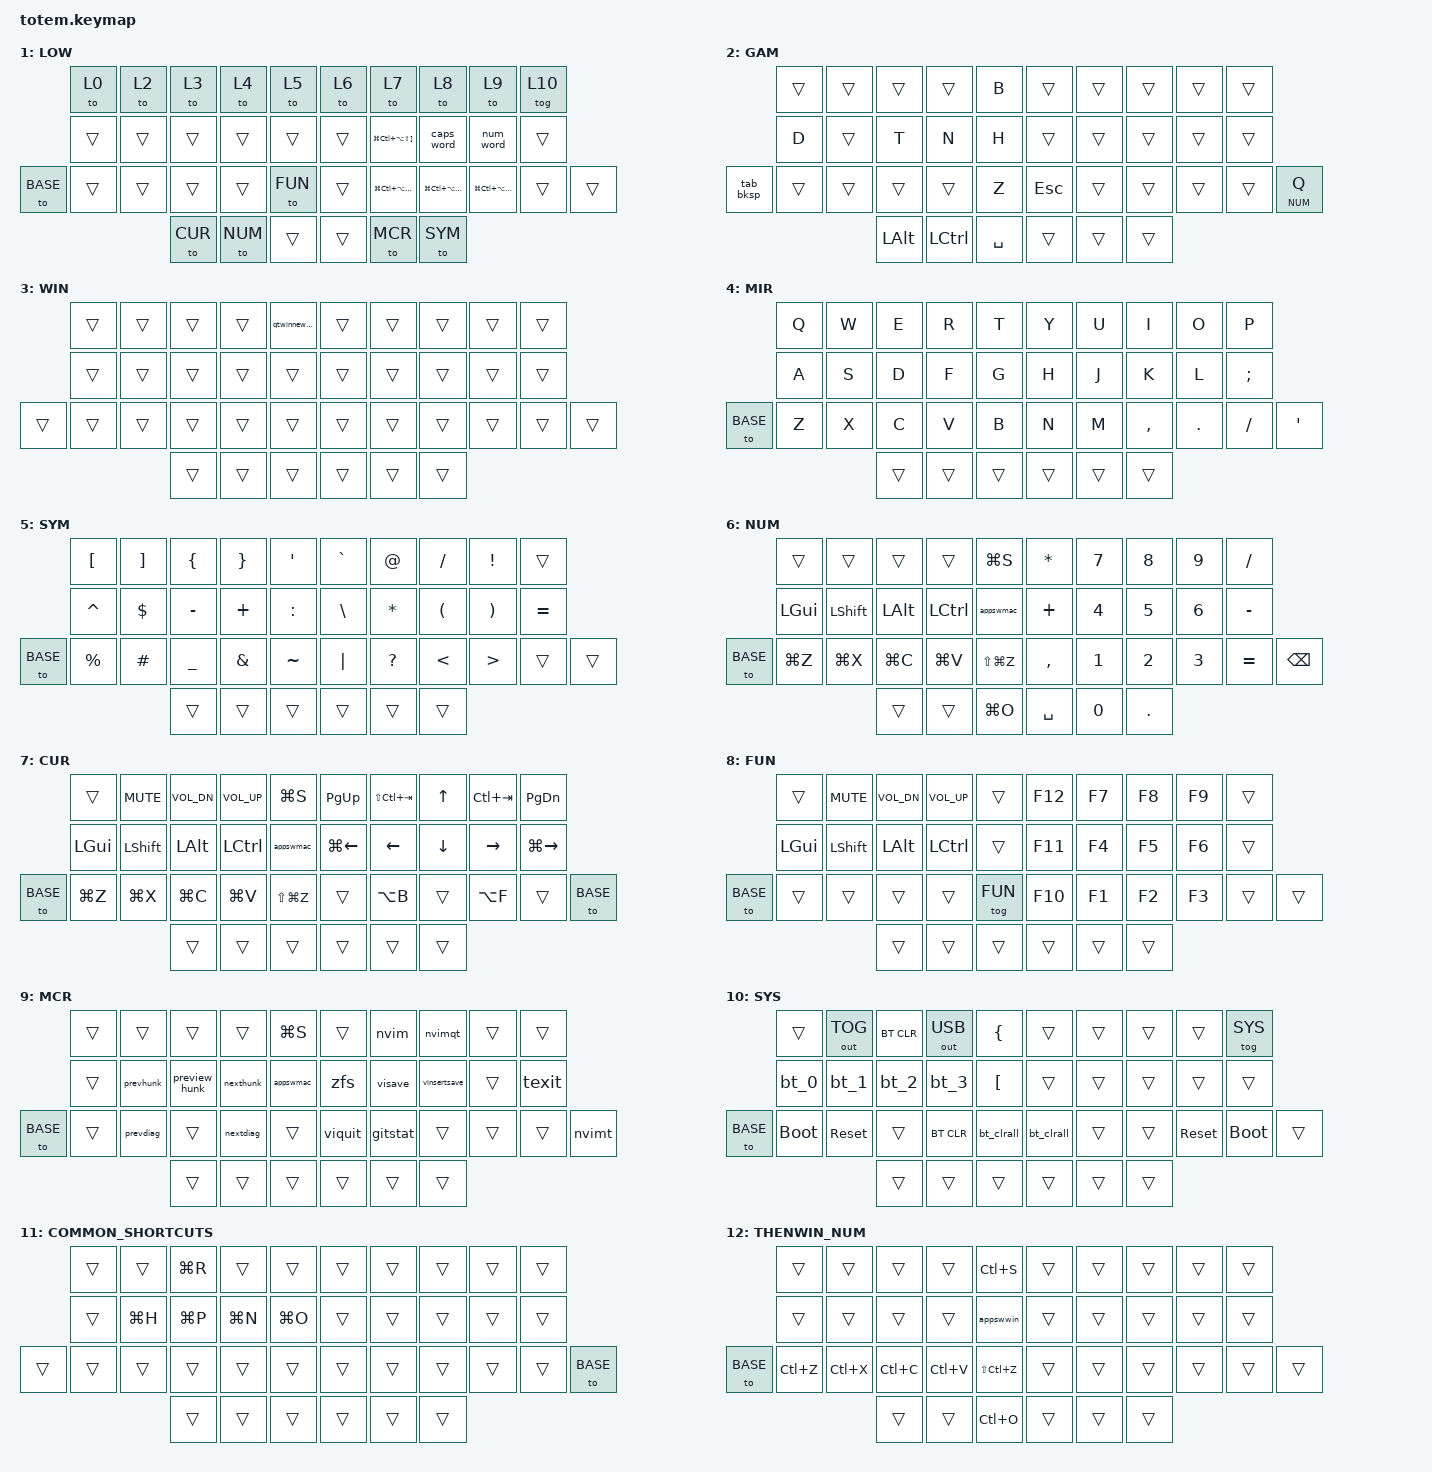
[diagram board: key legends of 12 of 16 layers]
//
//                                                        ▀▀▀▀▀     ▀▀▀▀▀          ▀▀█▀▀
//                                                        ▄▀▀▀▄  ▄  ▄▀▀▀▄  ▄  ▄▀▀▀▄  █  ▄▀▀▀▄
//                                                        █   █  █  █   █  █  █   █  █  █   █
//                                                         ▀▀▀   █   ▀▀▀   █   ▀▀▀   ▀   ▀▀▀
//                                                               █      ▄▄▄█▄▄▄    █   █
//                                                               ▀      █  █  █     █▄█
//                                                             ▀▀▀▀▀    █  █  █      ▀
//                                                                      ▀  ▀  ▀
//
// ▄▄▄▄▄▄▄▄▄▄▄▄▄▄▄▄▄▄▄▄▄▄▄▄▄▄▄▄▄▄▄▄▄▄▄▄▄▄▄▄▄▄▄▄▄▄▄▄▄▄▄▄▄▄▄▄▄▄▄▄▄▄▄▄▄▄▄▄▄▄▄▄▄▄▄▄▄▄▄▄▄▄▄▄▄▄▄▄▄▄▄▄▄▄▄▄▄▄▄▄▄▄▄▄▄▄▄▄▄▄▄▄▄▄▄▄▄▄▄▄▄▄▄▄▄▄▄▄▄▄▄▄▄▄▄▄▄▄▄▄▄▄▄▄▄▄▄▄▄


#include <behaviors.dtsi>
#include <dt-bindings/zmk/bt.h>
#include <dt-bindings/zmk/ext_power.h>
#include <dt-bindings/zmk/keys.h>
#include <dt-bindings/zmk/outputs.h>

#define BASE 0
#define LOW 1
#define GAM 2
#define WIN 3
#define MIR 4
#define SYM 5
#define NUM 6
#define CUR 7
#define FUN 8
#define MCR 9
#define SYS 10
#define COMMON_SHORTCUTS 11
#define THENWIN_NUM 12
#define THENWIN_CUR 13
#define THENWIN_MCR 14
#define THENWIN_SHORTCUTS 15
#define QWERTY 16


&mt {
  quick-tap-ms = <100>;
  global-quick-tap;
  flavor = "tap-preferred";
  tapping-term-ms = <170>;
};

#define HYPER LG(LC(LA(LSHFT)))
#define MEH   LC(LA(LSHFT))
#define HYPF7 &kp LG(LC(LA(LS(F7))))
#define HYPF8 &kp LG(LC(LA(LS(F8))))
#define HYPF9 &kp LG(LC(LA(LS(F9))))
#define ALFRED &kp LG(LC(LA(LS(RBKT))))
#define TMHP &tmb_hold_preferred // layer-tap for thumb keys with hold-preferred!
#define TM_MRPH_DEL &tmb_mrph_del

&num_word {
    layers = <NUM>;  // replace NUM by the location of numbers layer
    continue-list = <BSPC DEL DOT COMMA PLUS MINUS STAR FSLH EQUAL LSHFT LEFT RIGHT UP DOWN TAB>;
};

#include "custom.dtsi"
#include "custom-combos.dtsi"
#include "custom-behaviors.dtsi"
#include "custom-macros.dtsi"

/ {
        keymap {
                compatible = "zmk,keymap";
// ▄▄▄▄▄▄▄▄▄▄▄▄▄▄▄▄▄▄▄▄▄▄▄▄▄▄▄▄▄▄▄▄▄▄▄▄▄▄▄▄▄▄▄▄▄▄▄▄▄▄▄▄▄▄▄▄▄▄▄▄▄▄▄▄▄▄▄▄▄▄▄▄▄▄▄▄▄▄▄▄▄▄▄▄▄▄▄▄▄▄▄▄▄▄▄▄▄▄▄▄▄▄▄▄▄▄▄▄▄▄▄▄▄▄▄▄▄▄▄▄▄▄▄▄▄▄▄▄▄▄▄▄▄▄▄▄▄▄▄▄▄▄▄▄▄▄▄▄▄

                base_layer {
// ┏━━━━━━━━━━━━━━━━━━━━━━━━━━━━━━━━━━━━━━━┓
display-name= "BASE"                       ;
// ┗━━━━━━━━━━━━━━━━━━━━━━━━━━━━━━━━━━━━━━━┛
//              ┏━━━━━━━━━━━┳━━━━━━━━━━━┳━━━━━━━━━━━━━━━━━━┳━━━━━━━━━━━━━━━━━━┳━━━━━━━━━━━━━━━━┓   ┏━━━━━━━━━━━━━━━━━━┳━━━━━━━━━━━━━━━━━━┳━━━━━━━━━━━━━━━━┳━━━━━━━━━━━┳━━━━━━━━━━━┓
//              ┃     B     ┃     Y     ┃     O            ┃     U            ┃     " (New TAB)┃   ┃      ;           ┃      L           ┃     D          ┃     W     ┃  V (MEH)  ┃
//              ┣━━━━━━━━━━━╋━━━━━━━━━━━╋━━━━━━━━━━━━━━━━━━╋━━━━━━━━━━━━━━━━━━╋━━━━━━━━━━━━━━━━┫   ┣━━━━━━━━━━━━━━━━━━╋━━━━━━━━━━━━━━━━━━╋━━━━━━━━━━━━━━━━╋━━━━━━━━━━━╋━━━━━━━━━━━┫
//              ┃ C (LGUI)  ┃     I     ┃     E (ALT)      ┃     A (CTRL)     ┃     , (SHFT)   ┃   ┃      . (SHFT)    ┃      H (CTRL)    ┃     T (ALT)    ┃     S     ┃     N     ┃
// ┏━━━━━━━━━━━━╋━━━━━━━━━━━╋━━━━━━━━━━━╋━━━━━━━━━━━━━━━━━━╋━━━━━━━━━━━━━━━━━━╋━━━━━━━━━━━━━━━━┫   ┣━━━━━━━━━━━━━━━━━━╋━━━━━━━━━━━━━━━━━━╋━━━━━━━━━━━━━━━━╋━━━━━━━━━━━╋━━━━━━━━━━━╋━━━━━━━━━━━┓
// ┃Z(SHORTCUTS)┃     J     ┃     X     ┃     K            ┃     G            ┃     / (FUN)    ┃   ┃      _ (HYPER)   ┃      R           ┃     M          ┃     F     ┃     P     ┃     Q     ┃
// ┗━━━━━━━━━━━━┻━━━━━━━━━━━┻━━━━━━━━━━━╋━━━━━━━━━━━━━━━━━━╋━━━━━━━━━━━━━━━━━━╋━━━━━━━━━━━━━━━━┫   ┣━━━━━━━━━━━━━━━━━━╋━━━━━━━━━━━━━━━━━━╋━━━━━━━━━━━━━━━━╋━━━━━━━━━━━┻━━━━━━━━━━━┻━━━━━━━━━━━┛
//                                      ┃   ESC (Cursor)   ┃    BSPC (Num)    ┃   TAB (GUI)    ┃   ┃   ENTER(Lower)   ┃    SPC (Macro)   ┃  DEL (Symbols) ┃
//                                      ┗━━━━━━━━━━━━━━━━━━┻━━━━━━━━━━━━━━━━━━┻━━━━━━━━━━━━━━━━┛   ┗━━━━━━━━━━━━━━━━━━┻━━━━━━━━━━━━━━━━━━┻━━━━━━━━━━━━━━━━┛
 bindings = <
// ╷            ╷           ╷           ╷                  ╷                  ╷                ╷   ╷                  ╷                  ╷                ╷           ╷           ╷           ╷

                 &kp W       &kp G       &kp M              &kp L              &qtmacnewtab         &kp SEMI           &kp U              &kp O            &kp B       &mmt MEH V
                 &hl LGUI D  &kp S       &hl LALT T         &hl LCTRL N        &hl LSHFT COMMA      &hr RSHFT DOT      &hr RCTRL A        &hr RALT E       &kp I       &hr RGUI H
    &z_shrt_gr   &kp F       &kp X       &kp C              &kp R              &ltl FUN FSLH        &mmt HYPER UNDER   &kp P              &kp Y            &kp J       &kp K       &kp Q
                                         TMHP CUR ESC       TM_MRPH_DEL NUM 0  &mmt LGUI TAB        &tmb LOW RET       &tmb MCR SPACE     TMHP SYM DEL

                        >;
                 };

// ▄▄▄▄▄▄▄▄▄▄▄▄▄▄▄▄▄▄▄▄▄▄▄▄▄▄▄▄▄▄▄▄▄▄▄▄▄▄▄▄▄▄▄▄▄▄▄▄▄▄▄▄▄▄▄▄▄▄▄▄▄▄▄▄▄▄▄▄▄▄▄▄▄▄▄▄▄▄▄▄▄▄▄▄▄▄▄▄▄▄▄▄▄▄▄▄▄▄▄▄▄▄▄▄▄▄▄▄▄▄▄▄▄▄▄▄▄▄▄▄▄▄▄▄▄▄▄▄▄▄▄▄▄▄▄▄▄▄▄▄▄▄▄▄▄▄▄▄▄


                lower_layer {
// ┏━━━━━━━━━━━━━━━━━━━━━━━━━━━━━━━━━━━━━━━┓
display-name= "LOW"                        ;
// ┗━━━━━━━━━━━━━━━━━━━━━━━━━━━━━━━━━━━━━━━┛
//             ┏━━━━━━━━━━━┳━━━━━━━━━━━┳━━━━━━━━━━━┳━━━━━━━━━━━┳━━━━━━━━━━━┓   ┏━━━━━━━━━━━┳━━━━━━━━━━━┳━━━━━━━━━━━┳━━━━━━━━━━━┳━━━━━━━━━━━┓
//             ┃    L0     ┃    L2     ┃     L3    ┃    L4     ┃    L5     ┃   ┃    L6     ┃    L7     ┃    L8     ┃    L9     ┃    L10    ┃
//             ┣━━━━━━━━━━━╋━━━━━━━━━━━╋━━━━━━━━━━━╋━━━━━━━━━━━╋━━━━━━━━━━━┫   ┣━━━━━━━━━━━╋━━━━━━━━━━━╋━━━━━━━━━━━╋━━━━━━━━━━━╋━━━━━━━━━━━┫
//             ┃           ┃           ┃           ┃           ┃           ┃   ┃           ┃  Alfred   ┃ &capswrd  ┃ &num_word ┃           ┃
// ┏━━━━━━━━━━━╋━━━━━━━━━━━╋━━━━━━━━━━━╋━━━━━━━━━━━╋━━━━━━━━━━━╋━━━━━━━━━━━┫   ┣━━━━━━━━━━━╋━━━━━━━━━━━╋━━━━━━━━━━━╋━━━━━━━━━━━╋━━━━━━━━━━━╋━━━━━━━━━━━┓
// ┃   L0      ┃           ┃           ┃           ┃           ┃    FUN    ┃   ┃           ┃ HYP_F7    ┃ HYP_F8    ┃  HYP_F9   ┃           ┃           ┃
// ┗━━━━━━━━━━━┻━━━━━━━━━━━┻━━━━━━━━━━━╋━━━━━━━━━━━╋━━━━━━━━━━━╋━━━━━━━━━━━┫   ┣━━━━━━━━━━━╋━━━━━━━━━━━╋━━━━━━━━━━━╋━━━━━━━━━━━┻━━━━━━━━━━━┻━━━━━━━━━━━┛
//                                     ┃    CUR    ┃    NUM    ┃           ┃   ┃           ┃   Macro   ┃    SYM    ┃
//                                     ┗━━━━━━━━━━━┻━━━━━━━━━━━┻━━━━━━━━━━━┛   ┗━━━━━━━━━━━┻━━━━━━━━━━━┻━━━━━━━━━━━┛
 bindings = <
// ╷           ╷           ╷           ╷           ╷           ╷           ╷   ╷           ╷           ╷           ╷           ╷           ╷           ╷

                &to 0       &to 2       &to 3       &to 4       &to 5           &to 6       &to 7       &to 8       &to 9       &tog 10
                &trans      &trans      &trans      &trans      &trans          &trans      ALFRED      &caps_word  &num_word   &trans
    &to BASE    &trans      &trans      &trans      &trans      &to FUN         &trans      HYPF7       HYPF8       HYPF9       &trans      &trans
                                        &to CUR     &to NUM     &trans          &trans      &to MCR     &to SYM
                        >;
                };

// ▄▄▄▄▄▄▄▄▄▄▄▄▄▄▄▄▄▄▄▄▄▄▄▄▄▄▄▄▄▄▄▄▄▄▄▄▄▄▄▄▄▄▄▄▄▄▄▄▄▄▄▄▄▄▄▄▄▄▄▄▄▄▄▄▄▄▄▄▄▄▄▄▄▄▄▄▄▄▄▄▄▄▄▄▄▄▄▄▄▄▄▄▄▄▄▄▄▄▄▄▄▄▄▄▄▄▄▄▄▄▄▄▄▄▄▄▄▄▄▄▄▄▄▄▄▄▄▄▄▄▄▄▄▄▄▄▄▄▄▄▄▄▄▄▄▄▄▄▄


                game_layer {
// ┏━━━━━━━━━━━━━━━━━━━━━━━━━━━━━━━━━━━━━━━┓
display-name= "GAM"                        ;
// ┗━━━━━━━━━━━━━━━━━━━━━━━━━━━━━━━━━━━━━━━┛
//           ┏━━━━━━━━━━━┳━━━━━━━━━━━┳━━━━━━━━━━━┳━━━━━━━━━━━┳━━━━━━━━━━━┓   ┏━━━━━━━━━━━┳━━━━━━━━━━━┳━━━━━━━━━━━┳━━━━━━━━━━━┳━━━━━━━━━━━┓
//           ┃           ┃           ┃           ┃           ┃     B     ┃   ┃           ┃           ┃           ┃           ┃           ┃
//           ┣━━━━━━━━━━━╋━━━━━━━━━━━╋━━━━━━━━━━━╋━━━━━━━━━━━╋━━━━━━━━━━━┫   ┣━━━━━━━━━━━╋━━━━━━━━━━━╋━━━━━━━━━━━╋━━━━━━━━━━━╋━━━━━━━━━━━┫
//           ┃     D     ┃           ┃     T     ┃     N     ┃     H     ┃   ┃           ┃           ┃           ┃           ┃           ┃
// ┏━━━━━━━━━╋━━━━━━━━━━━╋━━━━━━━━━━━╋━━━━━━━━━━━╋━━━━━━━━━━━╋━━━━━━━━━━━┫   ┣━━━━━━━━━━━╋━━━━━━━━━━━╋━━━━━━━━━━━╋━━━━━━━━━━━╋━━━━━━━━━━━╋━━━━━━━━━━━┓
// ┃TAB/BKSP ┃           ┃           ┃           ┃           ┃     Z     ┃   ┃    ESC    ┃           ┃           ┃           ┃           ┃  Q (NUM)  ┃
// ┗━━━━━━━━━┻━━━━━━━━━━━┻━━━━━━━━━━━╋━━━━━━━━━━━╋━━━━━━━━━━━╋━━━━━━━━━━━┫   ┣━━━━━━━━━━━╋━━━━━━━━━━━╋━━━━━━━━━━━╋━━━━━━━━━━━┻━━━━━━━━━━━┻━━━━━━━━━━━┛
//                                   ┃   LALT    ┃   LCTRL   ┃   SPACE   ┃   ┃           ┃           ┃           ┃
//                                   ┗━━━━━━━━━━━┻━━━━━━━━━━━┻━━━━━━━━━━━┛   ┗━━━━━━━━━━━┻━━━━━━━━━━━┻━━━━━━━━━━━┛
 bindings = <
// ╷         ╷           ╷           ╷           ╷           ╷           ╷   ╷           ╷           ╷           ╷           ╷           ╷           ╷

               &trans     &trans      &trans      &trans      &kp B           &trans      &trans      &trans      &trans      &trans
               &kp D      &trans      &kp T       &kp N       &kp H           &trans      &trans      &trans      &trans      &trans
    &tab_bksp  &trans     &trans      &trans      &trans      &kp Z           &kp ESC     &trans      &trans      &trans      &trans      &ltl NUM Q
                                      &kp LALT    &kp LCTRL   &kp SPACE       &trans      &trans      &trans
                        >;
                };

// ▄▄▄▄▄▄▄▄▄▄▄▄▄▄▄▄▄▄▄▄▄▄▄▄▄▄▄▄▄▄▄▄▄▄▄▄▄▄▄▄▄▄▄▄▄▄▄▄▄▄▄▄▄▄▄▄▄▄▄▄▄▄▄▄▄▄▄▄▄▄▄▄▄▄▄▄▄▄▄▄▄▄▄▄▄▄▄▄▄▄▄▄▄▄▄▄▄▄▄▄▄▄▄▄▄▄▄▄▄▄▄▄▄▄▄▄▄▄▄▄▄▄▄▄▄▄▄▄▄▄▄▄▄▄▄▄▄▄▄▄▄▄▄▄▄▄▄▄▄


                windows_layer {
// ┏━━━━━━━━━━━━━━━━━━━━━━━━━━━━━━━━━━━━━━━┓
display-name= "WIN"                        ;
// ┗━━━━━━━━━━━━━━━━━━━━━━━━━━━━━━━━━━━━━━━┛
//             ┏━━━━━━━━━━━┳━━━━━━━━━━━┳━━━━━━━━━━━┳━━━━━━━━━━━┳━━━━━━━━━━━┓   ┏━━━━━━━━━━━┳━━━━━━━━━━━┳━━━━━━━━━━━┳━━━━━━━━━━━┳━━━━━━━━━━━┓
//             ┃           ┃           ┃           ┃           ┃ NEW TAB   ┃   ┃           ┃           ┃           ┃           ┃           ┃
//             ┣━━━━━━━━━━━╋━━━━━━━━━━━╋━━━━━━━━━━━╋━━━━━━━━━━━╋━━━━━━━━━━━┫   ┣━━━━━━━━━━━╋━━━━━━━━━━━╋━━━━━━━━━━━╋━━━━━━━━━━━╋━━━━━━━━━━━┫
//             ┃           ┃           ┃           ┃           ┃           ┃   ┃           ┃           ┃           ┃           ┃           ┃
// ┏━━━━━━━━━━━╋━━━━━━━━━━━╋━━━━━━━━━━━╋━━━━━━━━━━━╋━━━━━━━━━━━╋━━━━━━━━━━━┫   ┣━━━━━━━━━━━╋━━━━━━━━━━━╋━━━━━━━━━━━╋━━━━━━━━━━━╋━━━━━━━━━━━╋━━━━━━━━━━━┓
// ┃           ┃           ┃           ┃           ┃           ┃           ┃   ┃           ┃           ┃           ┃           ┃           ┃           ┃
// ┗━━━━━━━━━━━┻━━━━━━━━━━━┻━━━━━━━━━━━╋━━━━━━━━━━━╋━━━━━━━━━━━╋━━━━━━━━━━━┫   ┣━━━━━━━━━━━╋━━━━━━━━━━━╋━━━━━━━━━━━╋━━━━━━━━━━━┻━━━━━━━━━━━┻━━━━━━━━━━━┛
//                                     ┃           ┃           ┃           ┃   ┃           ┃           ┃           ┃
//                                     ┗━━━━━━━━━━━┻━━━━━━━━━━━┻━━━━━━━━━━━┛   ┗━━━━━━━━━━━┻━━━━━━━━━━━┻━━━━━━━━━━━┛
 bindings = <
// ╷           ╷           ╷           ╷           ╷           ╷           ╷   ╷           ╷           ╷           ╷           ╷           ╷           ╷

                &trans       &trans       &trans       &trans   &qtwinnewtab    &trans       &trans      &trans      &trans      &trans
                &trans       &trans       &trans       &trans   &trans          &trans       &trans      &trans      &trans      &trans
    &trans      &trans       &trans       &trans       &trans   &trans          &trans       &trans      &trans      &trans      &trans      &trans
                                          &trans       &trans   &trans          &trans       &trans      &trans
                        >;
                };

// ▄▄▄▄▄▄▄▄▄▄▄▄▄▄▄▄▄▄▄▄▄▄▄▄▄▄▄▄▄▄▄▄▄▄▄▄▄▄▄▄▄▄▄▄▄▄▄▄▄▄▄▄▄▄▄▄▄▄▄▄▄▄▄▄▄▄▄▄▄▄▄▄▄▄▄▄▄▄▄▄▄▄▄▄▄▄▄▄▄▄▄▄▄▄▄▄▄▄▄▄▄▄▄▄▄▄▄▄▄▄▄▄▄▄▄▄▄▄▄▄▄▄▄▄▄▄▄▄▄▄▄▄▄▄▄▄▄▄▄▄▄▄▄▄▄▄▄▄▄


                mirror_layer {
// ┏━━━━━━━━━━━━━━━━━━━━━━━━━━━━━━━━━━━━━━━┓
display-name= "MIR"                        ;
// ┗━━━━━━━━━━━━━━━━━━━━━━━━━━━━━━━━━━━━━━━┛
//             ┏━━━━━━━━━━━┳━━━━━━━━━━━┳━━━━━━━━━━━┳━━━━━━━━━━━┳━━━━━━━━━━━┓   ┏━━━━━━━━━━━┳━━━━━━━━━━━┳━━━━━━━━━━━┳━━━━━━━━━━━┳━━━━━━━━━━━┓
//             ┃ NEXT FILE ┃ MARK IN   ┃ ROTATE    ┃ MARK OUT  ┃ SHOW SNAP ┃   ┃           ┃           ┃           ┃           ┃           ┃
//             ┣━━━━━━━━━━━╋━━━━━━━━━━━╋━━━━━━━━━━━╋━━━━━━━━━━━╋━━━━━━━━━━━┫   ┣━━━━━━━━━━━╋━━━━━━━━━━━╋━━━━━━━━━━━╋━━━━━━━━━━━╋━━━━━━━━━━━┫
//             ┃ TVP II    ┃ LEFT      ┃ PAN       ┃ RIGHT     ┃ PLAY/FLIP ┃   ┃           ┃           ┃           ┃           ┃           ┃
// ┏━━━━━━━━━━━╋━━━━━━━━━━━╋━━━━━━━━━━━╋━━━━━━━━━━━╋━━━━━━━━━━━╋━━━━━━━━━━━┫   ┣━━━━━━━━━━━╋━━━━━━━━━━━╋━━━━━━━━━━━╋━━━━━━━━━━━╋━━━━━━━━━━━╋━━━━━━━━━━━┓
// ┃ TO BASE   ┃ SHIFT     ┃ COPY      ┃ DELETE    ┃ PASTE     ┃ IMG MARK  ┃   ┃           ┃           ┃           ┃           ┃           ┃           ┃
// ┗━━━━━━━━━━━┻━━━━━━━━━━━┻━━━━━━━━━━━╋━━━━━━━━━━━╋━━━━━━━━━━━╋━━━━━━━━━━━┫   ┣━━━━━━━━━━━╋━━━━━━━━━━━╋━━━━━━━━━━━╋━━━━━━━━━━━┻━━━━━━━━━━━┻━━━━━━━━━━━┛
//                                     ┃           ┃ UNDO/SAVE ┃  SEL/MOV  ┃   ┃           ┃           ┃           ┃
//                                     ┗━━━━━━━━━━━┻━━━━━━━━━━━┻━━━━━━━━━━━┛   ┗━━━━━━━━━━━┻━━━━━━━━━━━┻━━━━━━━━━━━┛
 bindings = <
// ╷           ╷           ╷           ╷           ╷           ╷           ╷   ╷           ╷           ╷           ╷           ╷           ╷           ╷

                &kp Q       &kp W       &kp E       &kp R       &kp T           &kp Y        &kp U        &kp I        &kp O     &kp P
                &kp A       &kp S       &kp D       &kp F       &kp G           &kp H        &kp J        &kp K        &kp L     &kp SEMI
    &to BASE    &kp Z       &kp X       &kp C       &kp V       &kp B           &kp N        &kp M        &kp COMMA    &kp DOT   &kp FSLH    &kp SQT
                                        &trans      &trans      &trans          &trans       &trans       &trans
                        >;
                };

// ▄▄▄▄▄▄▄▄▄▄▄▄▄▄▄▄▄▄▄▄▄▄▄▄▄▄▄▄▄▄▄▄▄▄▄▄▄▄▄▄▄▄▄▄▄▄▄▄▄▄▄▄▄▄▄▄▄▄▄▄▄▄▄▄▄▄▄▄▄▄▄▄▄▄▄▄▄▄▄▄▄▄▄▄▄▄▄▄▄▄▄▄▄▄▄▄▄▄▄▄▄▄▄▄▄▄▄▄▄▄▄▄▄▄▄▄▄▄▄▄▄▄▄▄▄▄▄▄▄▄▄▄▄▄▄▄▄▄▄▄▄▄▄▄▄▄▄▄▄


                symbols_layer {
// ┏━━━━━━━━━━━━━━━━━━━━━━━━━━━━━━━━━━━━━━━┓
display-name= "SYM"                        ;
// ┗━━━━━━━━━━━━━━━━━━━━━━━━━━━━━━━━━━━━━━━┛
//             ┏━━━━━━━━━━━┳━━━━━━━━━━━┳━━━━━━━━━━━┳━━━━━━━━━━━┳━━━━━━━━━━━┓   ┏━━━━━━━━━━━┳━━━━━━━━━━━┳━━━━━━━━━━━┳━━━━━━━━━━━┳━━━━━━━━━━━┓
//             ┃     [     ┃     ]     ┃     {     ┃     }     ┃     '     ┃   ┃     `     ┃     @     ┃     /     ┃     !     ┃           ┃
//             ┣━━━━━━━━━━━╋━━━━━━━━━━━╋━━━━━━━━━━━╋━━━━━━━━━━━╋━━━━━━━━━━━┫   ┣━━━━━━━━━━━╋━━━━━━━━━━━╋━━━━━━━━━━━╋━━━━━━━━━━━╋━━━━━━━━━━━┫
//             ┃     ^     ┃     $     ┃      -    ┃     +     ┃     :     ┃   ┃     \     ┃     *     ┃     (     ┃     )     ┃     =     ┃
// ┏━━━━━━━━━━━╋━━━━━━━━━━━╋━━━━━━━━━━━╋━━━━━━━━━━━╋━━━━━━━━━━━╋━━━━━━━━━━━┫   ┣━━━━━━━━━━━╋━━━━━━━━━━━╋━━━━━━━━━━━╋━━━━━━━━━━━╋━━━━━━━━━━━╋━━━━━━━━━━━┓
// ┃ TO BASE   ┃     %     ┃     #     ┃      _    ┃     &     ┃     ~     ┃   ┃     |     ┃     ?     ┃     <     ┃     >     ┃           ┃           ┃
// ┗━━━━━━━━━━━┻━━━━━━━━━━━┻━━━━━━━━━━━╋━━━━━━━━━━━╋━━━━━━━━━━━╋━━━━━━━━━━━┫   ┣━━━━━━━━━━━╋━━━━━━━━━━━╋━━━━━━━━━━━╋━━━━━━━━━━━┻━━━━━━━━━━━┻━━━━━━━━━━━┛
//                                     ┃           ┃           ┃           ┃   ┃           ┃           ┃           ┃
//                                     ┗━━━━━━━━━━━┻━━━━━━━━━━━┻━━━━━━━━━━━┛   ┗━━━━━━━━━━━┻━━━━━━━━━━━┻━━━━━━━━━━━┛
 bindings = <
// ╷           ╷           ╷           ╷           ╷           ╷           ╷   ╷           ╷           ╷           ╷           ╷           ╷           ╷

                &kp LBKT    &kp RBKT    &kp LBRC    &kp RBRC    &kp SQT         &kp GRAVE    &kp AT      &kp FSLH     &kp EXCL   &trans
                &kp CARET   &kp DLLR    &kp MINUS   &kp PLUS    &kp COLON       &kp BSLH     &kp ASTRK   &kp LPAR     &kp RPAR   &kp EQUAL
    &to BASE    &kp PRCNT   &kp HASH    &kp UNDER   &kp AMPS    &kp TILDE       &kp PIPE     &kp QMARK   &kp LT       &kp GT     &trans     &trans
                                        &trans      &trans      &trans          &trans       &trans      &trans
                        >;
                };

// ▄▄▄▄▄▄▄▄▄▄▄▄▄▄▄▄▄▄▄▄▄▄▄▄▄▄▄▄▄▄▄▄▄▄▄▄▄▄▄▄▄▄▄▄▄▄▄▄▄▄▄▄▄▄▄▄▄▄▄▄▄▄▄▄▄▄▄▄▄▄▄▄▄▄▄▄▄▄▄▄▄▄▄▄▄▄▄▄▄▄▄▄▄▄▄▄▄▄▄▄▄▄▄▄▄▄▄▄▄▄▄▄▄▄▄▄▄▄▄▄▄▄▄▄▄▄▄▄▄▄▄▄▄▄▄▄▄▄▄▄▄▄▄▄▄▄▄▄▄


                numbers_layer {
// ┏━━━━━━━━━━━━━━━━━━━━━━━━━━━━━━━━━━━━━━━┓
display-name= "NUM"                        ;
// ┗━━━━━━━━━━━━━━━━━━━━━━━━━━━━━━━━━━━━━━━┛
//             ┏━━━━━━━━━━━━┳━━━━━━━━━━━━┳━━━━━━━━━━━━━┳━━━━━━━━━━━━━┳━━━━━━━━━━━┓     ┏━━━━━━━━━━━┳━━━━━━━━━━━┳━━━━━━━━━━━┳━━━━━━━━━━━┳━━━━━━━━━━━━┓
//             ┃            ┃            ┃             ┃             ┃    SAVE   ┃     ┃     *     ┃     7     ┃     8     ┃     9     ┃     /      ┃
//             ┣━━━━━━━━━━━━╋━━━━━━━━━━━━╋━━━━━━━━━━━━━╋━━━━━━━━━━━━━╋━━━━━━━━━━━┫     ┣━━━━━━━━━━━╋━━━━━━━━━━━╋━━━━━━━━━━━╋━━━━━━━━━━━╋━━━━━━━━━━━━┫
//             ┃  LGUI      ┃   LSHFT    ┃    LALT     ┃    LCTRL    ┃  CMD+TAB  ┃     ┃     +     ┃     4     ┃     5     ┃     6     ┃     -      ┃
// ┏━━━━━━━━━━━╋━━━━━━━━━━━━╋━━━━━━━━━━━━╋━━━━━━━━━━━━━╋━━━━━━━━━━━━━╋━━━━━━━━━━━┫     ┣━━━━━━━━━━━╋━━━━━━━━━━━╋━━━━━━━━━━━╋━━━━━━━━━━━╋━━━━━━━━━━━━╋━━━━━━━━━┓
// ┃  TO BASE  ┃  UNDO      ┃    CUT     ┃    COPY     ┃    PASTE    ┃    REDO   ┃     ┃     ,     ┃     1     ┃     2     ┃     3     ┃     =      ┃  BKSPC  ┃
// ┗━━━━━━━━━━━┻━━━━━━━━━━━━┻━━━━━━━━━━━━╋━━━━━━━━━━━━━╋━━━━━━━━━━━━━╋━━━━━━━━━━━┫     ┣━━━━━━━━━━━╋━━━━━━━━━━━╋━━━━━━━━━━━╋━━━━━━━━━━━┻━━━━━━━━━━━━┻━━━━━━━━━┛
//                                       ┃             ┃             ┃   CMD+O   ┃     ┃    SPC    ┃     0     ┃    DOT    ┃
//                                       ┗━━━━━━━━━━━━━┻━━━━━━━━━━━━━┻━━━━━━━━━━━┛     ┗━━━━━━━━━━━┻━━━━━━━━━━━┻━━━━━━━━━━━┛
 bindings = <
// ╷           ╷            ╷            ╷             ╷             ╷            ╷    ╷           ╷           ╷           ╷           ╷            ╷         ╷

                &trans       &trans       &trans        &trans        &kp LG(S)         &kp STAR    &kp N7      &kp N8      &kp N9      &kp FSLH
                &kp LGUI     &kp LSHFT    &kp LALT      &kp LCTRL     &appswmac         &kp PLUS    &kp N4      &kp N5      &kp N6      &kp MINUS
    &to BASE    &kp LG(Z)    &kp LG(X)    &kp LG(C)     &kp LG(V)     &kp LS(LG(Z))     &kp COMMA   &kp N1      &kp N2      &kp N3      &kp EQUAL    &kp BSPC
                                          &trans        &trans        &kp LG(O)         &kp SPACE   &kp N0      &kp DOT
                        >;
                };

// ▄▄▄▄▄▄▄▄▄▄▄▄▄▄▄▄▄▄▄▄▄▄▄▄▄▄▄▄▄▄▄▄▄▄▄▄▄▄▄▄▄▄▄▄▄▄▄▄▄▄▄▄▄▄▄▄▄▄▄▄▄▄▄▄▄▄▄▄▄▄▄▄▄▄▄▄▄▄▄▄▄▄▄▄▄▄▄▄▄▄▄▄▄▄▄▄▄▄▄▄▄▄▄▄▄▄▄▄▄▄▄▄▄▄▄▄▄▄▄▄▄▄▄▄▄▄▄▄▄▄▄▄▄▄▄▄▄▄▄▄▄▄▄▄▄▄▄▄▄


                cursor_layer {
// ┏━━━━━━━━━━━━━━━━━━━━━━━━━━━━━━━━━━━━━━━┓
display-name= "CUR"                        ;
// ┗━━━━━━━━━━━━━━━━━━━━━━━━━━━━━━━━━━━━━━━┛
//             ┏━━━━━━━━━━━┳━━━━━━━━━━━━┳━━━━━━━━━━━━┳━━━━━━━━━━━━━┳━━━━━━━━━━━━━━┓    ┏━━━━━━━━━━━━━━┳━━━━━━━━━━━━━━━━┳━━━━━━━━━━━┳━━━━━━━━━━━━━━┳━━━━━━━━━━━━━━━┓
//             ┃           ┃    MUTE    ┃   VOL DN   ┃   VOL UP    ┃     SAVE     ┃    ┃     PG UP    ┃   PREV TAB     ┃    UP     ┃   NEXT TAB   ┃    PG DOWN    ┃
//             ┣━━━━━━━━━━━╋━━━━━━━━━━━━╋━━━━━━━━━━━━╋━━━━━━━━━━━━━╋━━━━━━━━━━━━━━┫    ┣━━━━━━━━━━━━━━╋━━━━━━━━━━━━━━━━╋━━━━━━━━━━━╋━━━━━━━━━━━━━━╋━━━━━━━━━━━━━━━┫
//             ┃    LGUI   ┃   LSHFT    ┃    LALT    ┃    LCTRL    ┃   CMD+TAB    ┃    ┃      bol     ┃     LEFT       ┃   DOWN    ┃    RIGHT     ┃     eol       ┃
// ┏━━━━━━━━━━━╋━━━━━━━━━━━╋━━━━━━━━━━━━╋━━━━━━━━━━━━╋━━━━━━━━━━━━━╋━━━━━━━━━━━━━━┫    ┣━━━━━━━━━━━━━━╋━━━━━━━━━━━━━━━━╋━━━━━━━━━━━╋━━━━━━━━━━━━━━╋━━━━━━━━━━━━━━━╋━━━━━━━━━━━┓
// ┃  TO BASE  ┃   UNDO    ┃    CUT     ┃    COPY    ┃    PASTE    ┃     REDO     ┃    ┃              ┃     ALT+B      ┃           ┃    ALT+F     ┃               ┃  TO BASE  ┃
// ┗━━━━━━━━━━━┻━━━━━━━━━━━┻━━━━━━━━━━━━╋━━━━━━━━━━━━╋━━━━━━━━━━━━━╋━━━━━━━━━━━━━━┫    ┣━━━━━━━━━━━━━━╋━━━━━━━━━━━━━━━━╋━━━━━━━━━━━╋━━━━━━━━━━━━━━┻━━━━━━━━━━━━━━━┻━━━━━━━━━━━┛
//                                      ┃            ┃             ┃              ┃    ┃              ┃                ┃           ┃
//                                      ┗━━━━━━━━━━━━┻━━━━━━━━━━━━━┻━━━━━━━━━━━━━━┛    ┗━━━━━━━━━━━━━━┻━━━━━━━━━━━━━━━━┻━━━━━━━━━━━┛
 bindings = <
 //╷           ╷           ╷           ╷             ╷             ╷              ╷    ╷              ╷                ╷           ╷              ╷               ╷           ╷

                &trans      &kp C_MUTE  &kp C_VOL_DN  &kp C_VOL_UP  &kp LG(S)           &kp PG_UP      &kp LS(LC(TAB))  &kp UP      &kp LC(TAB)    &kp PG_DN
                &kp LGUI    &kp LSHFT   &kp LALT      &kp LCTRL     &appswmac           &kp LG(LEFT)   &kp LEFT         &kp DOWN    &kp RIGHT      &kp LG(RIGHT)
    &to BASE    &kp LG(Z)   &kp LG(X)   &kp LG(C)     &kp LG(V)     &kp LS(LG(Z))       &trans         &kp LA(B)        &trans      &kp LA(F)      &trans          &to BASE
                                        &trans        &trans        &trans              &trans         &trans           &trans
                         >;
                };

// ▄▄▄▄▄▄▄▄▄▄▄▄▄▄▄▄▄▄▄▄▄▄▄▄▄▄▄▄▄▄▄▄▄▄▄▄▄▄▄▄▄▄▄▄▄▄▄▄▄▄▄▄▄▄▄▄▄▄▄▄▄▄▄▄▄▄▄▄▄▄▄▄▄▄▄▄▄▄▄▄▄▄▄▄▄▄▄▄▄▄▄▄▄▄▄▄▄▄▄▄▄▄▄▄▄▄▄▄▄▄▄▄▄▄▄▄▄▄▄▄▄▄▄▄▄▄▄▄▄▄▄▄▄▄▄▄▄▄▄▄▄▄▄▄▄▄▄▄▄


                functionkeys_layer {
// ┏━━━━━━━━━━━━━━━━━━━━━━━━━━━━━━━━━━━━━━━┓
display-name= "FUN"                        ;
// ┗━━━━━━━━━━━━━━━━━━━━━━━━━━━━━━━━━━━━━━━┛
//             ┏━━━━━━━━━━━┳━━━━━━━━━━━━━┳━━━━━━━━━━━━━┳━━━━━━━━━━━━━┳━━━━━━━━━━━┓        ┏━━━━━━━━━━━┳━━━━━━━━━━━┳━━━━━━━━━━━┳━━━━━━━━━━━┳━━━━━━━━━━━┓
//             ┃           ┃    MUTE     ┃    VOL DN   ┃    VOL UP   ┃           ┃        ┃    F12    ┃    F7     ┃    F8     ┃    F9     ┃           ┃
//             ┣━━━━━━━━━━━╋━━━━━━━━━━━━━╋━━━━━━━━━━━━━╋━━━━━━━━━━━━━╋━━━━━━━━━━━┫        ┣━━━━━━━━━━━╋━━━━━━━━━━━╋━━━━━━━━━━━╋━━━━━━━━━━━╋━━━━━━━━━━━┫
//             ┃    LGUI   ┃   LSHFT     ┃    LALT     ┃    LCTRL    ┃           ┃        ┃    F11    ┃    F4     ┃    F5     ┃    F6     ┃           ┃
// ┏━━━━━━━━━━━╋━━━━━━━━━━━╋━━━━━━━━━━━━━╋━━━━━━━━━━━━━╋━━━━━━━━━━━━━╋━━━━━━━━━━━┫        ┣━━━━━━━━━━━╋━━━━━━━━━━━╋━━━━━━━━━━━╋━━━━━━━━━━━╋━━━━━━━━━━━╋━━━━━━━━━━━┓
// ┃  TO BASE  ┃           ┃             ┃             ┃             ┃  TOG FUN  ┃        ┃    F10    ┃    F1     ┃    F2     ┃    F3     ┃           ┃           ┃
// ┗━━━━━━━━━━━┻━━━━━━━━━━━┻━━━━━━━━━━━━━╋━━━━━━━━━━━━━╋━━━━━━━━━━━━━╋━━━━━━━━━━━┫        ┣━━━━━━━━━━━╋━━━━━━━━━━━╋━━━━━━━━━━━╋━━━━━━━━━━━┻━━━━━━━━━━━┻━━━━━━━━━━━┛
//                                       ┃             ┃             ┃           ┃        ┃           ┃           ┃           ┃
//                                       ┗━━━━━━━━━━━━━┻━━━━━━━━━━━━━┻━━━━━━━━━━━┛        ┗━━━━━━━━━━━┻━━━━━━━━━━━┻━━━━━━━━━━━┛
 bindings = <
// ╷           ╷           ╷             ╷             ╷             ╷           ╷        ╷           ╷           ╷           ╷           ╷           ╷           ╷

                &trans      &kp C_MUTE    &kp C_VOL_DN  &kp C_VOL_UP  &trans               &kp F12     &kp F7      &kp F8      &kp F9      &trans
                &kp LGUI    &kp LSHFT     &kp LALT      &kp LCTRL     &trans               &kp F11     &kp F4      &kp F5      &kp F6      &trans
    &to BASE    &trans      &trans        &trans        &trans        &tog FUN             &kp F10     &kp F1      &kp F2      &kp F3      &trans      &trans
                                          &trans        &trans        &trans               &trans      &trans      &trans
                        >;
                };

// ▄▄▄▄▄▄▄▄▄▄▄▄▄▄▄▄▄▄▄▄▄▄▄▄▄▄▄▄▄▄▄▄▄▄▄▄▄▄▄▄▄▄▄▄▄▄▄▄▄▄▄▄▄▄▄▄▄▄▄▄▄▄▄▄▄▄▄▄▄▄▄▄▄▄▄▄▄▄▄▄▄▄▄▄▄▄▄▄▄▄▄▄▄▄▄▄▄▄▄▄▄▄▄▄▄▄▄▄▄▄▄▄▄▄▄▄▄▄▄▄▄▄▄▄▄▄▄▄▄▄▄▄▄▄▄▄▄▄▄▄▄▄▄▄▄▄▄▄▄


                macros_layer {
// ┏━━━━━━━━━━━━━━━━━━━━━━━━━━━━━━━━━━━━━━━┓
display-name= "MCR"                        ;
// ┗━━━━━━━━━━━━━━━━━━━━━━━━━━━━━━━━━━━━━━━┛
//             ┏━━━━━━━━━━━┳━━━━━━━━━━━┳━━━━━━━━━━━━━┳━━━━━━━━━━━┳━━━━━━━━━━━┓   ┏━━━━━━━━━━━┳━━━━━━━━━━━┳━━━━━━━━━━━━━━┳━━━━━━━━━━━┳━━━━━━━━━━━┓
//             ┃           ┃           ┃             ┃           ┃   SAVE    ┃   ┃           ┃  neovim   ┃   vimQuit    ┃           ┃           ┃
//             ┣━━━━━━━━━━━╋━━━━━━━━━━━╋━━━━━━━━━━━━━╋━━━━━━━━━━━╋━━━━━━━━━━━┫   ┣━━━━━━━━━━━╋━━━━━━━━━━━╋━━━━━━━━━━━━━━╋━━━━━━━━━━━╋━━━━━━━━━━━┫
//             ┃           ┃ PREV_HUNK ┃ Preview     ┃ NEXT_HUNK ┃  CMD+TAB  ┃   ┃    zfs    ┃  vimSave  ┃vimInsertSave ┃           ┃ exit + ↩  ┃
// ┏━━━━━━━━━━━╋━━━━━━━━━━━╋━━━━━━━━━━━╋━━━━━━━━━━━━━╋━━━━━━━━━━━╋━━━━━━━━━━━┫   ┣━━━━━━━━━━━╋━━━━━━━━━━━╋━━━━━━━━━━━━━━╋━━━━━━━━━━━╋━━━━━━━━━━━╋━━━━━━━━━━━┓
// ┃ TO BASE   ┃           ┃ PREV_DIAG ┃             ┃ NEXT_DIAG ┃           ┃   ┃vimSaveQuit┃git status ┃              ┃           ┃           ┃ nvim Term ┃
// ┗━━━━━━━━━━━┻━━━━━━━━━━━┻━━━━━━━━━━━╋━━━━━━━━━━━━━╋━━━━━━━━━━━╋━━━━━━━━━━━┫   ┣━━━━━━━━━━━╋━━━━━━━━━━━╋━━━━━━━━━━━━━━╋━━━━━━━━━━━┻━━━━━━━━━━━┻━━━━━━━━━━━┛
//                                     ┃             ┃           ┃           ┃   ┃           ┃           ┃              ┃
//                                     ┗━━━━━━━━━━━━━┻━━━━━━━━━━━┻━━━━━━━━━━━┛   ┗━━━━━━━━━━━┻━━━━━━━━━━━┻━━━━━━━━━━━━━━┛
 bindings = <
// ╷           ╷           ╷           ╷             ╷           ╷           ╷   ╷           ╷           ╷              ╷           ╷           ╷           ╷

                &trans      &trans      &trans        &trans      &kp LG(S)       &trans      &nvim       &nvimqt        &trans      &trans
                &trans      &prevhunk   &preview_hunk &nexthunk   &appswmac       &zfs        &visave     &vinsertsave   &trans      &texit
    &to BASE    &trans      &prevdiag   &trans        &nextdiag   &trans          &viquit     &gitstat    &trans         &trans      &trans       &nvimt
                                        &trans        &trans      &trans          &trans      &trans      &trans
                        >;
                };

// ▄▄▄▄▄▄▄▄▄▄▄▄▄▄▄▄▄▄▄▄▄▄▄▄▄▄▄▄▄▄▄▄▄▄▄▄▄▄▄▄▄▄▄▄▄▄▄▄▄▄▄▄▄▄▄▄▄▄▄▄▄▄▄▄▄▄▄▄▄▄▄▄▄▄▄▄▄▄▄▄▄▄▄▄▄▄▄▄▄▄▄▄▄▄▄▄▄▄▄▄▄▄▄▄▄▄▄▄▄▄▄▄▄▄▄▄▄▄▄▄▄▄▄▄▄▄▄▄▄▄▄▄▄▄▄▄▄▄▄▄▄▄▄▄▄▄▄▄▄


                system_layer {
// ┏━━━━━━━━━━━━━━━━━━━━━━━━━━━━━━━━━━━━━━━┓
display-name= "SYS"                        ;
// ┗━━━━━━━━━━━━━━━━━━━━━━━━━━━━━━━━━━━━━━━┛
//             ┏━━━━━━━━━━━┳━━━━━━━━━━━━━┳━━━━━━━━━━━━┳━━━━━━━━━━━┳━━━━━━━━━━━┓      ┏━━━━━━━━━━━┳━━━━━━━━━━━┳━━━━━━━━━━━┳━━━━━━━━━━━┳━━━━━━━━━━━┓
//             ┃           ┃TOGGLE OUT   ┃ BT_CLR     ┃ OUT USB   ┃     {     ┃      ┃           ┃           ┃           ┃           ┃  TOG SYS  ┃
//             ┣━━━━━━━━━━━╋━━━━━━━━━━━━━╋━━━━━━━━━━━━╋━━━━━━━━━━━╋━━━━━━━━━━━┫      ┣━━━━━━━━━━━╋━━━━━━━━━━━╋━━━━━━━━━━━╋━━━━━━━━━━━╋━━━━━━━━━━━┫
//             ┃ BT_SEL0   ┃ BT_SEL1     ┃ BT_SEL2    ┃ BT_SEL3   ┃     [     ┃      ┃           ┃           ┃           ┃           ┃           ┃
// ┏━━━━━━━━━━━╋━━━━━━━━━━━╋━━━━━━━━━━━━━╋━━━━━━━━━━━━╋━━━━━━━━━━━╋━━━━━━━━━━━┫      ┣━━━━━━━━━━━╋━━━━━━━━━━━╋━━━━━━━━━━━╋━━━━━━━━━━━╋━━━━━━━━━━━╋━━━━━━━━━━━┓
// ┃ TO BASE   ┃bootloader ┃ RESET       ┃            ┃  BT_CLR   ┃BT_CLR_ALL ┃      ┃BT_CLR_ALL ┃           ┃           ┃ RESET     ┃bootloader ┃           ┃
// ┗━━━━━━━━━━━┻━━━━━━━━━━━┻━━━━━━━━━━━━━╋━━━━━━━━━━━━╋━━━━━━━━━━━╋━━━━━━━━━━━┫      ┣━━━━━━━━━━━╋━━━━━━━━━━━╋━━━━━━━━━━━╋━━━━━━━━━━━┻━━━━━━━━━━━┻━━━━━━━━━━━┛
//                                       ┃            ┃           ┃           ┃      ┃           ┃           ┃           ┃
//                                       ┗━━━━━━━━━━━━┻━━━━━━━━━━━┻━━━━━━━━━━━┛      ┗━━━━━━━━━━━┻━━━━━━━━━━━┻━━━━━━━━━━━┛
 bindings = <
// ╷           ╷           ╷             ╷            ╷           ╷           ╷      ╷           ╷           ╷           ╷           ╷           ╷           ╷

                &trans      &out OUT_TOG &bt BT_CLR   &out OUT_USB &kp LBRC           &trans      &trans      &trans      &trans      &tog SYS
                &bt_0       &bt_1        &bt_2        &bt_3        &kp LBKT           &trans      &trans      &trans      &trans      &trans
    &to BASE    &bootloader &sys_reset   &trans       &bt BT_CLR   &bt_clrall         &bt_clrall  &trans      &trans      &sys_reset  &bootloader &trans
                                         &trans       &trans       &trans             &trans      &trans      &trans
                        >;
                };

// ▄▄▄▄▄▄▄▄▄▄▄▄▄▄▄▄▄▄▄▄▄▄▄▄▄▄▄▄▄▄▄▄▄▄▄▄▄▄▄▄▄▄▄▄▄▄▄▄▄▄▄▄▄▄▄▄▄▄▄▄▄▄▄▄▄▄▄▄▄▄▄▄▄▄▄▄▄▄▄▄▄▄▄▄▄▄▄▄▄▄▄▄▄▄▄▄▄▄▄▄▄▄▄▄▄▄▄▄▄▄▄▄▄▄▄▄▄▄▄▄▄▄▄▄▄▄▄▄▄▄▄▄▄▄▄▄▄▄▄▄▄▄▄▄▄▄▄▄▄

              shortcuts_layer {
// ┏━━━━━━━━━━━━━━━━━━━━━━━━━━━━━━━━━━━━━━━┓
display-name= "COMMON_SHORTCUTS"           ;
// ┗━━━━━━━━━━━━━━━━━━━━━━━━━━━━━━━━━━━━━━━┛
//             ┏━━━━━━━━━━━┳━━━━━━━━━━━┳━━━━━━━━━━━┳━━━━━━━━━━━┳━━━━━━━━━━━━┓    ┏━━━━━━━━━━━┳━━━━━━━━━━━┳━━━━━━━━━━━┳━━━━━━━━━━━┳━━━━━━━━━━━┓
//             ┃           ┃           ┃   CMD+R   ┃           ┃            ┃    ┃           ┃           ┃           ┃           ┃           ┃
//             ┣━━━━━━━━━━━╋━━━━━━━━━━━╋━━━━━━━━━━━╋━━━━━━━━━━━╋━━━━━━━━━━━━┫    ┣━━━━━━━━━━━╋━━━━━━━━━━━╋━━━━━━━━━━━╋━━━━━━━━━━━╋━━━━━━━━━━━┫
//             ┃           ┃   CMD+H   ┃   CMD+P   ┃   CMD+N   ┃    CMD+O   ┃    ┃           ┃           ┃           ┃           ┃           ┃
// ┏━━━━━━━━━━━╋━━━━━━━━━━━╋━━━━━━━━━━━╋━━━━━━━━━━━╋━━━━━━━━━━━╋━━━━━━━━━━━━┫    ┣━━━━━━━━━━━╋━━━━━━━━━━━╋━━━━━━━━━━━╋━━━━━━━━━━━╋━━━━━━━━━━━╋━━━━━━━━━━━┓
// ┃           ┃           ┃           ┃           ┃           ┃            ┃    ┃           ┃           ┃           ┃           ┃           ┃  TO BASE  ┃
// ┗━━━━━━━━━━━┻━━━━━━━━━━━┻━━━━━━━━━━━╋━━━━━━━━━━━╋━━━━━━━━━━━╋━━━━━━━━━━━━┫    ┣━━━━━━━━━━━╋━━━━━━━━━━━╋━━━━━━━━━━━╋━━━━━━━━━━━┻━━━━━━━━━━━┻━━━━━━━━━━━┛
//                                     ┃           ┃           ┃            ┃    ┃           ┃           ┃           ┃
//                                     ┗━━━━━━━━━━━┻━━━━━━━━━━━┻━━━━━━━━━━━━┛    ┗━━━━━━━━━━━┻━━━━━━━━━━━┻━━━━━━━━━━━┛
 bindings = <
// ╷           ╷           ╷           ╷           ╷           ╷            ╷    ╷           ╷           ╷           ╷           ╷           ╷           ╷

                &trans      &trans      &kp LG(R)   &trans      &trans            &trans      &trans      &trans      &trans      &trans
                &trans      &kp LG(H)   &kp LG(P)   &kp LG(N)   &kp LG(O)         &trans      &trans      &trans      &trans      &trans
    &trans      &trans      &trans      &trans      &trans      &trans            &trans      &trans      &trans      &trans      &trans      &to BASE
                                        &trans      &trans      &trans            &trans      &trans      &trans
                        >;
                };

// ▄▄▄▄▄▄▄▄▄▄▄▄▄▄▄▄▄▄▄▄▄▄▄▄▄▄▄▄▄▄▄▄▄▄▄▄▄▄▄▄▄▄▄▄▄▄▄▄▄▄▄▄▄▄▄▄▄▄▄▄▄▄▄▄▄▄▄▄▄▄▄▄▄▄▄▄▄▄▄▄▄▄▄▄▄▄▄▄▄▄▄▄▄▄▄▄▄▄▄▄▄▄▄▄▄▄▄▄▄▄▄▄▄▄▄▄▄▄▄▄▄▄▄▄▄▄▄▄▄▄▄▄▄▄▄▄▄▄▄▄▄▄▄▄▄▄▄▄▄

                then_numbers_layer {
// ┏━━━━━━━━━━━━━━━━━━━━━━━━━━━━━━━━━━━━━━━┓
display-name= "THENWIN_NUM"                ;
// ┗━━━━━━━━━━━━━━━━━━━━━━━━━━━━━━━━━━━━━━━┛
//             ┏━━━━━━━━━━━┳━━━━━━━━━━━┳━━━━━━━━━━━┳━━━━━━━━━━━┳━━━━━━━━━━━━━━┓    ┏━━━━━━━━━━━┳━━━━━━━━━━━┳━━━━━━━━━━━┳━━━━━━━━━━━┳━━━━━━━━━━━┓
//             ┃           ┃           ┃           ┃           ┃     SAVE     ┃    ┃           ┃           ┃           ┃           ┃           ┃
//             ┣━━━━━━━━━━━╋━━━━━━━━━━━╋━━━━━━━━━━━╋━━━━━━━━━━━╋━━━━━━━━━━━━━━┫    ┣━━━━━━━━━━━╋━━━━━━━━━━━╋━━━━━━━━━━━╋━━━━━━━━━━━╋━━━━━━━━━━━┫
//             ┃           ┃           ┃           ┃           ┃    ALT+TAB   ┃    ┃           ┃           ┃           ┃           ┃           ┃
// ┏━━━━━━━━━━━╋━━━━━━━━━━━╋━━━━━━━━━━━╋━━━━━━━━━━━╋━━━━━━━━━━━╋━━━━━━━━━━━━━━┫    ┣━━━━━━━━━━━╋━━━━━━━━━━━╋━━━━━━━━━━━╋━━━━━━━━━━━╋━━━━━━━━━━━╋━━━━━━━━━━━┓
// ┃  TO BASE  ┃   UNDO    ┃    CUT    ┃    COPY   ┃   PASTE   ┃     REDO     ┃    ┃           ┃           ┃           ┃           ┃           ┃           ┃
// ┗━━━━━━━━━━━┻━━━━━━━━━━━┻━━━━━━━━━━━╋━━━━━━━━━━━╋━━━━━━━━━━━╋━━━━━━━━━━━━━━┫    ┣━━━━━━━━━━━╋━━━━━━━━━━━╋━━━━━━━━━━━╋━━━━━━━━━━━┻━━━━━━━━━━━┻━━━━━━━━━━━┛
//                                     ┃           ┃           ┃    CTRL+O    ┃    ┃           ┃           ┃           ┃
//                                     ┗━━━━━━━━━━━┻━━━━━━━━━━━┻━━━━━━━━━━━━━━┛    ┗━━━━━━━━━━━┻━━━━━━━━━━━┻━━━━━━━━━━━┛
 bindings = <
// ╷           ╷           ╷           ╷           ╷           ╷              ╷    ╷           ╷           ╷           ╷           ╷           ╷           ╷

                &trans      &trans      &trans      &trans      &kp LC(S)           &trans      &trans      &trans      &trans      &trans
                &trans      &trans      &trans      &trans      &appswwin           &trans      &trans      &trans      &trans      &trans
    &to BASE    &kp LC(Z)   &kp LC(X)   &kp LC(C)   &kp LC(V)   &kp LS(LC(Z))       &trans      &trans      &trans      &trans      &trans      &trans
                                        &trans      &trans      &kp LC(O)           &trans      &trans      &trans
                        >;
                };

// ▄▄▄▄▄▄▄▄▄▄▄▄▄▄▄▄▄▄▄▄▄▄▄▄▄▄▄▄▄▄▄▄▄▄▄▄▄▄▄▄▄▄▄▄▄▄▄▄▄▄▄▄▄▄▄▄▄▄▄▄▄▄▄▄▄▄▄▄▄▄▄▄▄▄▄▄▄▄▄▄▄▄▄▄▄▄▄▄▄▄▄▄▄▄▄▄▄▄▄▄▄▄▄▄▄▄▄▄▄▄▄▄▄▄▄▄▄▄▄▄▄▄▄▄▄▄▄▄▄▄▄▄▄▄▄▄▄▄▄▄▄▄▄▄▄▄▄▄▄

                then_cursor_layer {
// ┏━━━━━━━━━━━━━━━━━━━━━━━━━━━━━━━━━━━━━━━┓
display-name= "THENWIN_CUR"                ;
// ┗━━━━━━━━━━━━━━━━━━━━━━━━━━━━━━━━━━━━━━━┛
//             ┏━━━━━━━━━━━┳━━━━━━━━━━━┳━━━━━━━━━━━┳━━━━━━━━━━━┳━━━━━━━━━━━━━━┓     ┏━━━━━━━━━━━┳━━━━━━━━━━━┳━━━━━━━━━━━┳━━━━━━━━━━┳━━━━━━━━━━━┓
//             ┃           ┃           ┃           ┃           ┃     SAVE     ┃     ┃           ┃           ┃           ┃          ┃           ┃
//             ┣━━━━━━━━━━━╋━━━━━━━━━━━╋━━━━━━━━━━━╋━━━━━━━━━━━╋━━━━━━━━━━━━━━┫     ┣━━━━━━━━━━━╋━━━━━━━━━━━╋━━━━━━━━━━━╋━━━━━━━━━━╋━━━━━━━━━━━┫
//             ┃           ┃           ┃           ┃           ┃    ALT+TAB   ┃     ┃    Home   ┃           ┃           ┃          ┃   End     ┃
// ┏━━━━━━━━━━━╋━━━━━━━━━━━╋━━━━━━━━━━━╋━━━━━━━━━━━╋━━━━━━━━━━━╋━━━━━━━━━━━━━━┫     ┣━━━━━━━━━━━╋━━━━━━━━━━━╋━━━━━━━━━━━╋━━━━━━━━━━╋━━━━━━━━━━━╋━━━━━━━━━━━┓
// ┃  TO BASE  ┃   UNDO    ┃    CUT    ┃    COPY   ┃   PASTE   ┃     REDO     ┃     ┃           ┃           ┃           ┃          ┃           ┃           ┃
// ┗━━━━━━━━━━━┻━━━━━━━━━━━┻━━━━━━━━━━━╋━━━━━━━━━━━╋━━━━━━━━━━━╋━━━━━━━━━━━━━━┫     ┣━━━━━━━━━━━╋━━━━━━━━━━━╋━━━━━━━━━━━╋━━━━━━━━━━┻━━━━━━━━━━━┻━━━━━━━━━━━┛
//                                     ┃           ┃           ┃              ┃     ┃           ┃           ┃           ┃
//                                     ┗━━━━━━━━━━━┻━━━━━━━━━━━┻━━━━━━━━━━━━━━┛     ┗━━━━━━━━━━━┻━━━━━━━━━━━┻━━━━━━━━━━━┛
 bindings = <
// ╷           ╷           ╷           ╷           ╷           ╷              ╷     ╷           ╷           ╷           ╷          ╷           ╷           ╷

                &trans      &trans      &trans      &trans      &kp LC(S)            &trans      &trans      &trans      &trans     &trans
                &trans      &trans      &trans      &trans      &appswwin            &kp HOME    &trans      &trans      &trans     &kp END
    &to BASE    &kp LC(Z)   &kp LC(X)   &kp LC(C)   &kp LC(V)   &kp LS(LC(Z))        &trans      &trans      &trans      &trans     &trans      &trans
                                        &trans      &trans      &trans               &trans      &trans      &trans
                        >;
                };

// ▄▄▄▄▄▄▄▄▄▄▄▄▄▄▄▄▄▄▄▄▄▄▄▄▄▄▄▄▄▄▄▄▄▄▄▄▄▄▄▄▄▄▄▄▄▄▄▄▄▄▄▄▄▄▄▄▄▄▄▄▄▄▄▄▄▄▄▄▄▄▄▄▄▄▄▄▄▄▄▄▄▄▄▄▄▄▄▄▄▄▄▄▄▄▄▄▄▄▄▄▄▄▄▄▄▄▄▄▄▄▄▄▄▄▄▄▄▄▄▄▄▄▄▄▄▄▄▄▄▄▄▄▄▄▄▄▄▄▄▄▄▄▄▄▄▄▄▄▄

                then_macros_layer {
// ┏━━━━━━━━━━━━━━━━━━━━━━━━━━━━━━━━━━━━━━━┓
display-name= "THENWIN_MCR"                ;
// ┗━━━━━━━━━━━━━━━━━━━━━━━━━━━━━━━━━━━━━━━┛
//             ┏━━━━━━━━━━━┳━━━━━━━━━━━┳━━━━━━━━━━━┳━━━━━━━━━━━┳━━━━━━━━━━━┓    ┏━━━━━━━━━━━┳━━━━━━━━━━━┳━━━━━━━━━━━┳━━━━━━━━━━━┳━━━━━━━━━━━┓
//             ┃           ┃           ┃           ┃           ┃   SAVE    ┃    ┃           ┃           ┃           ┃           ┃           ┃
//             ┣━━━━━━━━━━━╋━━━━━━━━━━━╋━━━━━━━━━━━╋━━━━━━━━━━━╋━━━━━━━━━━━┫    ┣━━━━━━━━━━━╋━━━━━━━━━━━╋━━━━━━━━━━━╋━━━━━━━━━━━╋━━━━━━━━━━━┫
//             ┃           ┃           ┃           ┃           ┃  ALT+TAB  ┃    ┃           ┃           ┃           ┃           ┃           ┃
// ┏━━━━━━━━━━━╋━━━━━━━━━━━╋━━━━━━━━━━━╋━━━━━━━━━━━╋━━━━━━━━━━━╋━━━━━━━━━━━┫    ┣━━━━━━━━━━━╋━━━━━━━━━━━╋━━━━━━━━━━━╋━━━━━━━━━━━╋━━━━━━━━━━━╋━━━━━━━━━━━┓
// ┃  TO BASE  ┃           ┃           ┃           ┃           ┃           ┃    ┃           ┃           ┃           ┃           ┃           ┃           ┃
// ┗━━━━━━━━━━━┻━━━━━━━━━━━┻━━━━━━━━━━━╋━━━━━━━━━━━╋━━━━━━━━━━━╋━━━━━━━━━━━┫    ┣━━━━━━━━━━━╋━━━━━━━━━━━╋━━━━━━━━━━━╋━━━━━━━━━━━┻━━━━━━━━━━━┻━━━━━━━━━━━┛
//                                     ┃           ┃           ┃           ┃    ┃           ┃           ┃           ┃
//                                     ┗━━━━━━━━━━━┻━━━━━━━━━━━┻━━━━━━━━━━━┛    ┗━━━━━━━━━━━┻━━━━━━━━━━━┻━━━━━━━━━━━┛
 bindings = <
// ╷           ╷           ╷           ╷           ╷           ╷           ╷    ╷           ╷           ╷           ╷           ╷           ╷           ╷

                &trans      &trans      &trans      &trans      &kp LC(S)        &trans      &trans      &trans      &trans      &trans
                &trans      &trans      &trans      &trans      &appswwin        &trans      &trans      &trans      &trans      &trans
    &to BASE    &trans      &trans      &trans      &trans      &trans           &trans      &trans      &trans      &trans      &trans      &trans
                                        &trans      &trans      &trans           &trans      &trans      &trans
                        >;
                };

// ▄▄▄▄▄▄▄▄▄▄▄▄▄▄▄▄▄▄▄▄▄▄▄▄▄▄▄▄▄▄▄▄▄▄▄▄▄▄▄▄▄▄▄▄▄▄▄▄▄▄▄▄▄▄▄▄▄▄▄▄▄▄▄▄▄▄▄▄▄▄▄▄▄▄▄▄▄▄▄▄▄▄▄▄▄▄▄▄▄▄▄▄▄▄▄▄▄▄▄▄▄▄▄▄▄▄▄▄▄▄▄▄▄▄▄▄▄▄▄▄▄▄▄▄▄▄▄▄▄▄▄▄▄▄▄▄▄▄▄▄▄▄▄▄▄▄▄▄▄

              then_shortcuts_layer {
// ┏━━━━━━━━━━━━━━━━━━━━━━━━━━━━━━━━━━━━━━━┓
display-name= "THENWIN_SHORTCUTS"          ;
// ┗━━━━━━━━━━━━━━━━━━━━━━━━━━━━━━━━━━━━━━━┛
//             ┏━━━━━━━━━━━┳━━━━━━━━━━━┳━━━━━━━━━━━┳━━━━━━━━━━━┳━━━━━━━━━━━━┓    ┏━━━━━━━━━━━┳━━━━━━━━━━━┳━━━━━━━━━━━┳━━━━━━━━━━━┳━━━━━━━━━━━┓
//             ┃           ┃           ┃   CTRL+R  ┃           ┃            ┃    ┃           ┃           ┃           ┃           ┃           ┃
//             ┣━━━━━━━━━━━╋━━━━━━━━━━━╋━━━━━━━━━━━╋━━━━━━━━━━━╋━━━━━━━━━━━━┫    ┣━━━━━━━━━━━╋━━━━━━━━━━━╋━━━━━━━━━━━╋━━━━━━━━━━━╋━━━━━━━━━━━┫
//             ┃           ┃  CTRL+H   ┃   CTRL+P  ┃  CTRL+N   ┃   CTRL+O   ┃    ┃           ┃           ┃           ┃           ┃           ┃
// ┏━━━━━━━━━━━╋━━━━━━━━━━━╋━━━━━━━━━━━╋━━━━━━━━━━━╋━━━━━━━━━━━╋━━━━━━━━━━━━┫    ┣━━━━━━━━━━━╋━━━━━━━━━━━╋━━━━━━━━━━━╋━━━━━━━━━━━╋━━━━━━━━━━━╋━━━━━━━━━━━┓
// ┃           ┃           ┃           ┃           ┃           ┃            ┃    ┃           ┃           ┃           ┃           ┃           ┃  TO BASE  ┃
// ┗━━━━━━━━━━━┻━━━━━━━━━━━┻━━━━━━━━━━━╋━━━━━━━━━━━╋━━━━━━━━━━━╋━━━━━━━━━━━━┫    ┣━━━━━━━━━━━╋━━━━━━━━━━━╋━━━━━━━━━━━╋━━━━━━━━━━━┻━━━━━━━━━━━┻━━━━━━━━━━━┛
//                                     ┃           ┃           ┃            ┃    ┃           ┃           ┃           ┃
//                                     ┗━━━━━━━━━━━┻━━━━━━━━━━━┻━━━━━━━━━━━━┛    ┗━━━━━━━━━━━┻━━━━━━━━━━━┻━━━━━━━━━━━┛
 bindings = <
// ╷           ╷           ╷           ╷           ╷           ╷            ╷    ╷           ╷           ╷           ╷           ╷           ╷           ╷

                &trans      &trans      &kp LC(R)   &trans      &trans            &trans      &trans      &trans      &trans      &trans
                &trans      &kp LC(H)   &kp LC(P)   &kp LC(N)   &kp LC(O)         &trans      &trans      &trans      &trans      &trans
    &trans      &trans      &trans      &trans      &trans      &trans            &trans      &trans      &trans      &trans      &trans      &to BASE
                                        &trans      &trans      &trans            &trans      &trans      &trans
                        >;
                };

// ▄▄▄▄▄▄▄▄▄▄▄▄▄▄▄▄▄▄▄▄▄▄▄▄▄▄▄▄▄▄▄▄▄▄▄▄▄▄▄▄▄▄▄▄▄▄▄▄▄▄▄▄▄▄▄▄▄▄▄▄▄▄▄▄▄▄▄▄▄▄▄▄▄▄▄▄▄▄▄▄▄▄▄▄▄▄▄▄▄▄▄▄▄▄▄▄▄▄▄▄▄▄▄▄▄▄▄▄▄▄▄▄▄▄▄▄▄▄▄▄▄▄▄▄▄▄▄▄▄▄▄▄▄▄▄▄▄▄▄▄▄▄▄▄▄▄▄▄▄

                // tvp1_layer {
// // ┏━━━━━━━━━━━━━━━━━━━━━━━━━━━━━━━━━━━━━━━┓
// label= "TVP 1"                             ;
// // ┗━━━━━━━━━━━━━━━━━━━━━━━━━━━━━━━━━━━━━━━┛
// //             ┏━━━━━━━━━━━┳━━━━━━━━━━━┳━━━━━━━━━━━┳━━━━━━━━━━━┳━━━━━━━━━━━┓   ┏━━━━━━━━━━━┳━━━━━━━━━━━┳━━━━━━━━━━━┳━━━━━━━━━━━┳━━━━━━━━━━━┓
// //             ┃ NEXT FILE ┃ MARK IN   ┃ ROTATE    ┃ MARK OUT  ┃ SHOW SNAP ┃   ┃           ┃           ┃           ┃           ┃           ┃
// //             ┣━━━━━━━━━━━╋━━━━━━━━━━━╋━━━━━━━━━━━╋━━━━━━━━━━━╋━━━━━━━━━━━┫   ┣━━━━━━━━━━━╋━━━━━━━━━━━╋━━━━━━━━━━━╋━━━━━━━━━━━╋━━━━━━━━━━━┫
// //             ┃ TVP II    ┃ LEFT      ┃ PAN       ┃ RIGHT     ┃ PLAY/FLIP ┃   ┃           ┃           ┃           ┃           ┃           ┃
// // ┏━━━━━━━━━━━╋━━━━━━━━━━━╋━━━━━━━━━━━╋━━━━━━━━━━━╋━━━━━━━━━━━╋━━━━━━━━━━━┫   ┣━━━━━━━━━━━╋━━━━━━━━━━━╋━━━━━━━━━━━╋━━━━━━━━━━━╋━━━━━━━━━━━╋━━━━━━━━━━━┓
// // ┃ FULLSCR   ┃ SHIFT     ┃ COPY      ┃ DELETE    ┃ PASTE     ┃ IMG MARK  ┃   ┃           ┃           ┃           ┃           ┃           ┃           ┃
// // ┗━━━━━━━━━━━┻━━━━━━━━━━━┻━━━━━━━━━━━╋━━━━━━━━━━━╋━━━━━━━━━━━╋━━━━━━━━━━━┫   ┣━━━━━━━━━━━╋━━━━━━━━━━━╋━━━━━━━━━━━╋━━━━━━━━━━━┻━━━━━━━━━━━┻━━━━━━━━━━━┛
// //                                     ┃           ┃ UNDO/SAVE ┃  SEL/MOV  ┃   ┃           ┃           ┃           ┃
// //                                     ┗━━━━━━━━━━━┻━━━━━━━━━━━┻━━━━━━━━━━━┛   ┗━━━━━━━━━━━┻━━━━━━━━━━━┻━━━━━━━━━━━┛
 // bindings = <
// // ╷           ╷           ╷           ╷           ╷           ╷           ╷   ╷           ╷           ╷           ╷           ╷           ╷           ╷

                // &kp TAB     &kp I       &kp LC(LALT) &kp O      &kp LC(F20)     &trans       &trans       &trans       &trans       &trans
                // &lt CUR L   &kp LEFT    &kp LALT    &kp RIGHT   &kp SPACE       &trans       &trans       &trans       &trans       &trans
    // &kp J       &kp LSHFT   &kp LC(C)   &kp BSPC    &kp LC(V)   &kp LC(F19)     &trans       &trans       &trans       &trans       &trans       &trans
                //                         &trans      &kp LC(F14) &kp LC(F13)     &trans       &trans       &trans
                //         >;
                // };

// // ▄▄▄▄▄▄▄▄▄▄▄▄▄▄▄▄▄▄▄▄▄▄▄▄▄▄▄▄▄▄▄▄▄▄▄▄▄▄▄▄▄▄▄▄▄▄▄▄▄▄▄▄▄▄▄▄▄▄▄▄▄▄▄▄▄▄▄▄▄▄▄▄▄▄▄▄▄▄▄▄▄▄▄▄▄▄▄▄▄▄▄▄▄▄▄▄▄▄▄▄▄▄▄▄▄▄▄▄▄▄▄▄▄▄▄▄▄▄▄▄▄▄▄▄▄▄▄▄▄▄▄▄▄▄▄▄▄▄▄▄▄▄▄▄▄▄▄▄▄


                // tvp2_layer {
// // ┏━━━━━━━━━━━━━━━━━━━━━━━━━━━━━━━━━━━━━━━┓
// label= "TVP 2"                             ;
// // ┗━━━━━━━━━━━━━━━━━━━━━━━━━━━━━━━━━━━━━━━┛
// //             ┏━━━━━━━━━━━┳━━━━━━━━━━━┳━━━━━━━━━━━┳━━━━━━━━━━━┳━━━━━━━━━━━┓   ┏━━━━━━━━━━━┳━━━━━━━━━━━┳━━━━━━━━━━━┳━━━━━━━━━━━┳━━━━━━━━━━━┓
// //             ┃ SOLO      ┃ TOGGLE IN ┃ RESET ROT ┃ TOGGLE OUT┃ TAKE SNAP ┃   ┃           ┃           ┃           ┃           ┃           ┃
// //             ┣━━━━━━━━━━━╋━━━━━━━━━━━╋━━━━━━━━━━━╋━━━━━━━━━━━╋━━━━━━━━━━━┫   ┣━━━━━━━━━━━╋━━━━━━━━━━━╋━━━━━━━━━━━╋━━━━━━━━━━━╋━━━━━━━━━━━┫
// //             ┃ ---       ┃ LAST KEY  ┃ NEW KEY   ┃ NEXT KEY  ┃ ENTER     ┃   ┃           ┃           ┃           ┃           ┃           ┃
// // ┏━━━━━━━━━━━╋━━━━━━━━━━━╋━━━━━━━━━━━╋━━━━━━━━━━━╋━━━━━━━━━━━╋━━━━━━━━━━━┫   ┣━━━━━━━━━━━╋━━━━━━━━━━━╋━━━━━━━━━━━╋━━━━━━━━━━━╋━━━━━━━━━━━╋━━━━━━━━━━━┓
// // ┃           ┃ FULLSCR   ┃ CPY2BRUSH ┃ DEL HEAD  ┃ PSTinPLACE┃ BOOK MARK ┃   ┃           ┃           ┃           ┃           ┃           ┃           ┃
// // ┗━━━━━━━━━━━┻━━━━━━━━━━━┻━━━━━━━━━━━╋━━━━━━━━━━━╋━━━━━━━━━━━╋━━━━━━━━━━━┫   ┣━━━━━━━━━━━╋━━━━━━━━━━━╋━━━━━━━━━━━╋━━━━━━━━━━━┻━━━━━━━━━━━┻━━━━━━━━━━━┛
// //                                     ┃           ┃ REDO/SAV1 ┃TRANS/WARP ┃   ┃           ┃           ┃           ┃
// //                                     ┗━━━━━━━━━━━┻━━━━━━━━━━━┻━━━━━━━━━━━┛   ┗━━━━━━━━━━━┻━━━━━━━━━━━┻━━━━━━━━━━━┛
 // bindings = <
// // ╷           ╷           ╷           ╷           ╷           ╷           ╷   ╷           ╷           ╷           ╷           ╷           ╷           ╷

                // &kp LC(F18) &kp LS(I)  &kp LS(HOME) &kp LS(O)   &kp LS(F)       &trans      &kp F7      &kp F8      &kp F9      &kp F12
                // &trans      &kp LS(LEFT) &kp LC(F17) &kp LS(RIGHT) &kp RET      &trans      &kp F4      &kp F5      &kp F6      &kp F11
    // &trans      &kp J       &kp LS(C)   &kp LC(F16) &kp LS(V)   &kp LC(F15)     &trans      &kp F1      &kp F2      &kp F3      &kp F10     &trans
                //                         &trans      &kp LC(F12) &kp LC(F11)     &trans      &trans      &trans
                //         >;
                // };
        };
};
